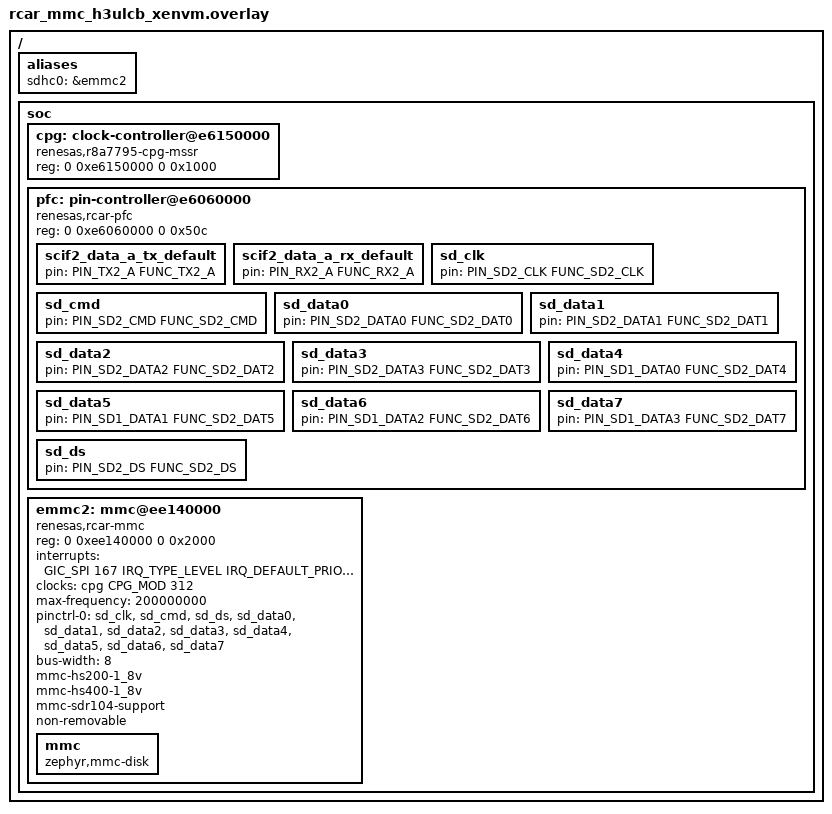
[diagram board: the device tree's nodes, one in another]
/*
 * Copyright (c) 2023 EPAM Systems
 *
 * SPDX-License-Identifier: Apache-2.0
 */

#include <arm64/armv8-a.dtsi>
#include <zephyr/dt-bindings/pinctrl/renesas/pinctrl-r8a77951.h>
#include <zephyr/dt-bindings/clock/r8a7795_cpg_mssr.h>

/ {
	#address-cells = <2>;
	#size-cells = <2>;

	/* These aliases are provided for compatibility with samples */
	aliases {
		sdhc0 = &emmc2;
	};

	soc: soc {
		#address-cells = <2>;
		#size-cells = <2>;

		cpg: clock-controller@e6150000 {
			compatible = "renesas,r8a7795-cpg-mssr";
			reg = <0 0xe6150000 0 0x1000>;
			#clock-cells = <2>;
			#power-domain-cells = <0>;
			#reset-cells = <1>;
			status = "okay";
		};

		pfc: pin-controller@e6060000 {
			compatible = "renesas,rcar-pfc";
			reg = <0 0xe6060000 0 0x50c>;

			scif2_data_a_tx_default: scif2_data_a_tx_default {
				pin = <PIN_TX2_A FUNC_TX2_A>;
			};

			scif2_data_a_rx_default: scif2_data_a_rx_default {
				pin = <PIN_RX2_A FUNC_RX2_A>;
			};

			sd_clk: sd_clk {
				pin = <PIN_SD2_CLK FUNC_SD2_CLK>;
			};

			sd_cmd: sd_cmd {
				pin = <PIN_SD2_CMD FUNC_SD2_CMD>;
			};

			sd_data0: sd_data0 {
				pin = <PIN_SD2_DATA0 FUNC_SD2_DAT0>;
			};

			sd_data1: sd_data1 {
				pin = <PIN_SD2_DATA1 FUNC_SD2_DAT1>;
			};

			sd_data2: sd_data2 {
				pin = <PIN_SD2_DATA2 FUNC_SD2_DAT2>;
			};

			sd_data3: sd_data3 {
				pin = <PIN_SD2_DATA3 FUNC_SD2_DAT3>;
			};

			sd_data4: sd_data4 {
				pin = <PIN_SD1_DATA0 FUNC_SD2_DAT4>;
			};

			sd_data5: sd_data5 {
				pin = <PIN_SD1_DATA1 FUNC_SD2_DAT5>;
			};

			sd_data6: sd_data6 {
				pin = <PIN_SD1_DATA2 FUNC_SD2_DAT6>;
			};

			sd_data7: sd_data7 {
				pin = <PIN_SD1_DATA3 FUNC_SD2_DAT7>;
			};

			sd_ds: sd_ds {
				pin = <PIN_SD2_DS FUNC_SD2_DS>;
			};
			status = "okay";
		};

		emmc2: mmc@ee140000 {
			compatible = "renesas,rcar-mmc";
			reg = <0 0xee140000 0 0x2000>;
			interrupts = <GIC_SPI 167 IRQ_TYPE_LEVEL IRQ_DEFAULT_PRIORITY>;
			clocks = <&cpg CPG_MOD 312>;
			max-frequency = <200000000>;

			pinctrl-0 = <&sd_clk &sd_cmd &sd_ds
					&sd_data0 &sd_data1 &sd_data2 &sd_data3
					&sd_data4 &sd_data5 &sd_data6 &sd_data7>;
			pinctrl-names = "default";

			bus-width = <8>;
			mmc-hs200-1_8v;
			mmc-hs400-1_8v;
			mmc-sdr104-support;
			non-removable;

			mmc {
				compatible = "zephyr,mmc-disk";
				status = "okay";
			};

			status = "okay";
		};
	};
};
